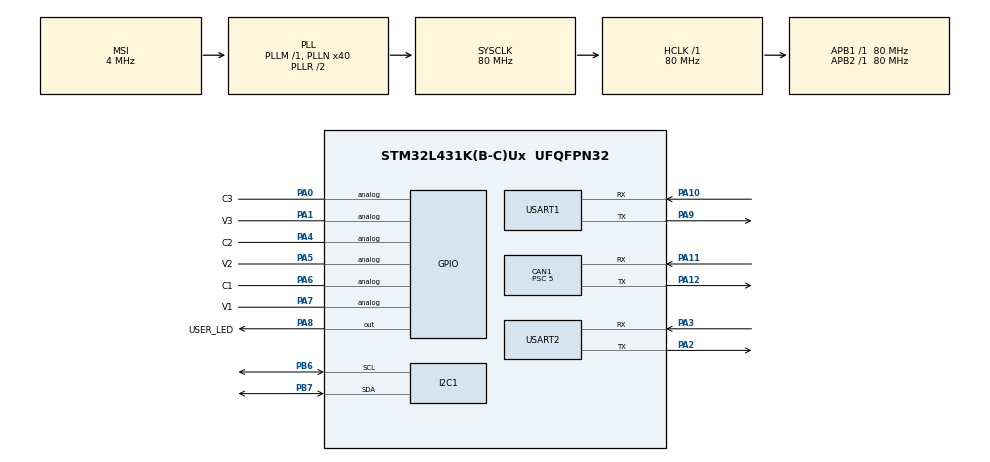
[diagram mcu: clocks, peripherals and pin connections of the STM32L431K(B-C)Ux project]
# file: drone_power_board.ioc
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CAN1.BS1=CAN_BS1_13TQ
CAN1.BS2=CAN_BS2_2TQ
CAN1.CalculateBaudRate=1000000
CAN1.CalculateTimeBit=1000
CAN1.CalculateTimeQuantum=62.5
CAN1.Prescaler=5
I2C1.Timing=0x10D19CE4
Mcu.Family=STM32L4
Mcu.Name=STM32L431K(B-C)Ux
Mcu.Package=UFQFPN32
NVIC.PriorityGroup=NVIC_PRIORITYGROUP_4
PA0.GPIO_Label=C3
PA0.Signal=GPIO_Analog
PA1.GPIO_Label=V3
PA1.Signal=GPIO_Analog
PA10.Mode=Asynchronous
PA10.Signal=USART1_RX
PA11.Mode=CAN_Activate
PA11.Signal=CAN1_RX
PA12.Mode=CAN_Activate
PA12.Signal=CAN1_TX
PA13\ (JTMS-SWDIO).Mode=Serial_Wire
PA13\ (JTMS-SWDIO).Signal=SYS_JTMS-SWDIO
PA14\ (JTCK-SWCLK).Mode=Serial_Wire
PA14\ (JTCK-SWCLK).Signal=SYS_JTCK-SWCLK
PA2.Mode=Asynchronous
PA2.Signal=USART2_TX
PA3.Mode=Asynchronous
PA3.Signal=USART2_RX
PA4.GPIO_Label=C2
PA4.Signal=GPIO_Analog
PA5.GPIO_Label=V2
PA5.Signal=GPIO_Analog
PA6.GPIO_Label=C1
PA6.Signal=GPIO_Analog
PA7.GPIO_Label=V1
PA7.Signal=GPIO_Analog
PA8.GPIO_Label=USER_LED
PA8.Signal=GPIO_Output
PA9.Mode=Asynchronous
PA9.Signal=USART1_TX
PB6.Mode=I2C
PB6.Signal=I2C1_SCL
PB7.Mode=I2C
PB7.Signal=I2C1_SDA
ProjectManager.HeapSize=0x200
ProjectManager.StackSize=0x400
ProjectManager.TargetToolchain=STM32CubeIDE
RCC.AHBFreq_Value=80000000
RCC.APB1Freq_Value=80000000
RCC.APB1TimFreq_Value=80000000
RCC.APB2Freq_Value=80000000
RCC.APB2TimFreq_Value=80000000
RCC.CortexFreq_Value=80000000
RCC.HCLKFreq_Value=80000000
RCC.HSE_VALUE=8000000
RCC.HSI48_VALUE=48000000
RCC.HSI_VALUE=16000000
RCC.LSE_VALUE=32768
RCC.MSI_VALUE=4000000
RCC.PLLN=40
RCC.SYSCLKFreq_VALUE=80000000
RCC.SYSCLKSource=RCC_SYSCLKSOURCE_PLLCLK
RCC.VCOOutputFreq_Value=160000000
USART1.VirtualMode-Asynchronous=VM_ASYNC
USART2.VirtualMode-Asynchronous=VM_ASYNC
board=custom

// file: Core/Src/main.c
/* USER CODE BEGIN Header */
/**
  ******************************************************************************
  * @file           : main.c
  * @brief          : Main program body
  ******************************************************************************
  * @attention
  *
  * Copyright (c) 2025 STMicroelectronics.
  * All rights reserved.
  *
  * This software is licensed under terms that can be found in the LICENSE file
  * in the root directory of this software component.
  * If no LICENSE file comes with this software, it is provided AS-IS.
  *
  ******************************************************************************
  */
/* USER CODE END Header */
#include "main.h"

/* USER CODE BEGIN Includes */
#include "canard.h"
#include "pca9685.h"
/* USER CODE END Includes */

CAN_HandleTypeDef hcan1;

I2C_HandleTypeDef hi2c1;

UART_HandleTypeDef huart1;
UART_HandleTypeDef huart2;

/* USER CODE BEGIN PV */
PCA9685_HandleTypeDef pca;
/* USER CODE END PV */

void SystemClock_Config(void);
static void MX_GPIO_Init(void);
static void MX_CAN1_Init(void);
static void MX_I2C1_Init(void);
static void MX_USART1_UART_Init(void);
static void MX_USART2_UART_Init(void);

int main(void)
{

  /* MCU Configuration--------------------------------------------------------*/

  /* Reset of all peripherals, Initializes the Flash interface and the Systick. */
  HAL_Init();

  /* Configure the system clock */
  SystemClock_Config();

  /* Initialize all configured peripherals */
  MX_GPIO_Init();
  MX_CAN1_Init();
  MX_I2C1_Init();
  MX_USART1_UART_Init();
  MX_USART2_UART_Init();
  /* USER CODE BEGIN 2 */
  pca.hi2c = &hi2c1;
  pca.address = PCA9685_DEFAULT_ADDRESS;
  PCA9685_Init(&pca, 50.0);
  /* USER CODE END 2 */

  /* Infinite loop */
  while (1)
  {

  }
}

void SystemClock_Config(void)
{
  RCC_OscInitTypeDef RCC_OscInitStruct = {0};
  RCC_ClkInitTypeDef RCC_ClkInitStruct = {0};

  /** Configure the main internal regulator output voltage
  */
  if (HAL_PWREx_ControlVoltageScaling(PWR_REGULATOR_VOLTAGE_SCALE1) != HAL_OK)
  {
    Error_Handler();
  }

  /** Initializes the RCC Oscillators according to the specified parameters
  * in the RCC_OscInitTypeDef structure.
  */
  RCC_OscInitStruct.OscillatorType = RCC_OSCILLATORTYPE_MSI;
  RCC_OscInitStruct.MSIState = RCC_MSI_ON;
  RCC_OscInitStruct.MSICalibrationValue = 0;
  RCC_OscInitStruct.MSIClockRange = RCC_MSIRANGE_6;
  RCC_OscInitStruct.PLL.PLLState = RCC_PLL_ON;
  RCC_OscInitStruct.PLL.PLLSource = RCC_PLLSOURCE_MSI;
  RCC_OscInitStruct.PLL.PLLM = 1;
  RCC_OscInitStruct.PLL.PLLN = 40;
  RCC_OscInitStruct.PLL.PLLP = RCC_PLLP_DIV7;
  RCC_OscInitStruct.PLL.PLLQ = RCC_PLLQ_DIV2;
  RCC_OscInitStruct.PLL.PLLR = RCC_PLLR_DIV2;
  if (HAL_RCC_OscConfig(&RCC_OscInitStruct) != HAL_OK)
  {
    Error_Handler();
  }

  /** Initializes the CPU, AHB and APB buses clocks
  */
  RCC_ClkInitStruct.ClockType = RCC_CLOCKTYPE_HCLK|RCC_CLOCKTYPE_SYSCLK
                              |RCC_CLOCKTYPE_PCLK1|RCC_CLOCKTYPE_PCLK2;
  RCC_ClkInitStruct.SYSCLKSource = RCC_SYSCLKSOURCE_PLLCLK;
  RCC_ClkInitStruct.AHBCLKDivider = RCC_SYSCLK_DIV1;
  RCC_ClkInitStruct.APB1CLKDivider = RCC_HCLK_DIV1;
  RCC_ClkInitStruct.APB2CLKDivider = RCC_HCLK_DIV1;

  if (HAL_RCC_ClockConfig(&RCC_ClkInitStruct, FLASH_LATENCY_4) != HAL_OK)
  {
    Error_Handler();
  }
}

static void MX_CAN1_Init(void)
{

  hcan1.Instance = CAN1;
  hcan1.Init.Prescaler = 5;
  hcan1.Init.Mode = CAN_MODE_NORMAL;
  hcan1.Init.SyncJumpWidth = CAN_SJW_1TQ;
  hcan1.Init.TimeSeg1 = CAN_BS1_13TQ;
  hcan1.Init.TimeSeg2 = CAN_BS2_2TQ;
  hcan1.Init.TimeTriggeredMode = DISABLE;
  hcan1.Init.AutoBusOff = DISABLE;
  hcan1.Init.AutoWakeUp = DISABLE;
  hcan1.Init.AutoRetransmission = DISABLE;
  hcan1.Init.ReceiveFifoLocked = DISABLE;
  hcan1.Init.TransmitFifoPriority = DISABLE;
  if (HAL_CAN_Init(&hcan1) != HAL_OK)
  {
    Error_Handler();
  }

}

static void MX_I2C1_Init(void)
{

  hi2c1.Instance = I2C1;
  hi2c1.Init.Timing = 0x10D19CE4;
  hi2c1.Init.OwnAddress1 = 0;
  hi2c1.Init.AddressingMode = I2C_ADDRESSINGMODE_7BIT;
  hi2c1.Init.DualAddressMode = I2C_DUALADDRESS_DISABLE;
  hi2c1.Init.OwnAddress2 = 0;
  hi2c1.Init.OwnAddress2Masks = I2C_OA2_NOMASK;
  hi2c1.Init.GeneralCallMode = I2C_GENERALCALL_DISABLE;
  hi2c1.Init.NoStretchMode = I2C_NOSTRETCH_DISABLE;
  if (HAL_I2C_Init(&hi2c1) != HAL_OK)
  {
    Error_Handler();
  }

  /** Configure Analogue filter
  */
  if (HAL_I2CEx_ConfigAnalogFilter(&hi2c1, I2C_ANALOGFILTER_ENABLE) != HAL_OK)
  {
    Error_Handler();
  }

  /** Configure Digital filter
  */
  if (HAL_I2CEx_ConfigDigitalFilter(&hi2c1, 0) != HAL_OK)
  {
    Error_Handler();
  }

}

static void MX_USART1_UART_Init(void)
{

  huart1.Instance = USART1;
  huart1.Init.BaudRate = 115200;
  huart1.Init.WordLength = UART_WORDLENGTH_8B;
  huart1.Init.StopBits = UART_STOPBITS_1;
  huart1.Init.Parity = UART_PARITY_NONE;
  huart1.Init.Mode = UART_MODE_TX_RX;
  huart1.Init.HwFlowCtl = UART_HWCONTROL_NONE;
  huart1.Init.OverSampling = UART_OVERSAMPLING_16;
  huart1.Init.OneBitSampling = UART_ONE_BIT_SAMPLE_DISABLE;
  huart1.AdvancedInit.AdvFeatureInit = UART_ADVFEATURE_NO_INIT;
  if (HAL_UART_Init(&huart1) != HAL_OK)
  {
    Error_Handler();
  }

}

static void MX_USART2_UART_Init(void)
{

  huart2.Instance = USART2;
  huart2.Init.BaudRate = 115200;
  huart2.Init.WordLength = UART_WORDLENGTH_8B;
  huart2.Init.StopBits = UART_STOPBITS_1;
  huart2.Init.Parity = UART_PARITY_NONE;
  huart2.Init.Mode = UART_MODE_TX_RX;
  huart2.Init.HwFlowCtl = UART_HWCONTROL_NONE;
  huart2.Init.OverSampling = UART_OVERSAMPLING_16;
  huart2.Init.OneBitSampling = UART_ONE_BIT_SAMPLE_DISABLE;
  huart2.AdvancedInit.AdvFeatureInit = UART_ADVFEATURE_NO_INIT;
  if (HAL_UART_Init(&huart2) != HAL_OK)
  {
    Error_Handler();
  }

}

static void MX_GPIO_Init(void)
{
  GPIO_InitTypeDef GPIO_InitStruct = {0};

  /* GPIO Ports Clock Enable */
  __HAL_RCC_GPIOA_CLK_ENABLE();
  __HAL_RCC_GPIOB_CLK_ENABLE();

  /*Configure GPIO pin Output Level */
  HAL_GPIO_WritePin(USER_LED_GPIO_Port, USER_LED_Pin, GPIO_PIN_RESET);

  /*Configure GPIO pins : C3_Pin V3_Pin C2_Pin V2_Pin
                           C1_Pin V1_Pin */
  GPIO_InitStruct.Pin = C3_Pin|V3_Pin|C2_Pin|V2_Pin
                          |C1_Pin|V1_Pin;
  GPIO_InitStruct.Mode = GPIO_MODE_ANALOG;
  GPIO_InitStruct.Pull = GPIO_NOPULL;
  HAL_GPIO_Init(GPIOA, &GPIO_InitStruct);

  /*Configure GPIO pin : USER_LED_Pin */
  GPIO_InitStruct.Pin = USER_LED_Pin;
  GPIO_InitStruct.Mode = GPIO_MODE_OUTPUT_PP;
  GPIO_InitStruct.Pull = GPIO_NOPULL;
  GPIO_InitStruct.Speed = GPIO_SPEED_FREQ_LOW;
  HAL_GPIO_Init(USER_LED_GPIO_Port, &GPIO_InitStruct);

}

void Error_Handler(void)
{
  __disable_irq();
  while (1)
  {
  }
}
